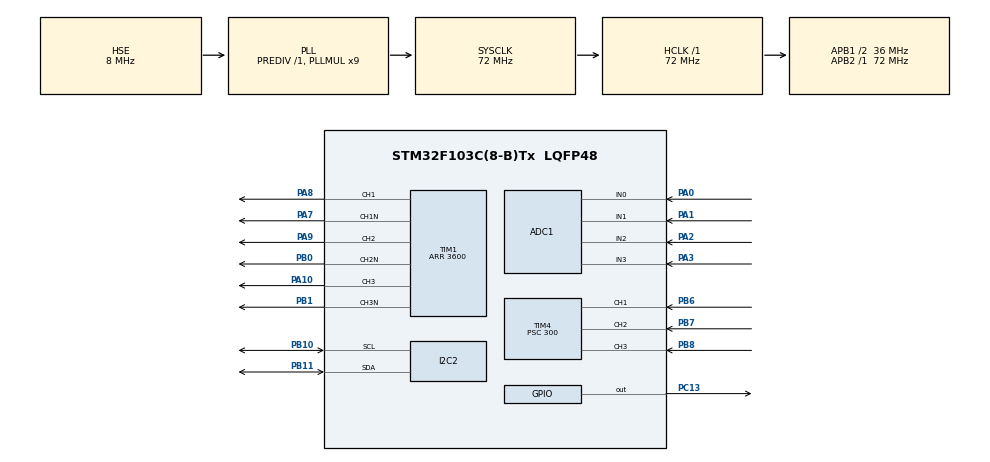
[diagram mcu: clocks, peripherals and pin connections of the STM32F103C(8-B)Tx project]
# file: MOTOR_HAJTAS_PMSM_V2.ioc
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ADC1.Channel-22\#ChannelInjectedConversion=ADC_CHANNEL_0
ADC1.Channel-24\#ChannelInjectedConversion=ADC_CHANNEL_1
ADC1.Channel-25\#ChannelInjectedConversion=ADC_CHANNEL_2
ADC1.Channel-26\#ChannelInjectedConversion=ADC_CHANNEL_3
ADC1.ContinuousConvMode=DISABLE
ADC1.DataAlign=ADC_DATAALIGN_RIGHT
ADC1.DiscontinuousConvMode=DISABLE
ADC1.EnableInjectedConversion=ENABLE
ADC1.EnableRegularConversion=DISABLE
ADC1.ExternalTrigInjecConv=ADC_EXTERNALTRIGINJECCONV_T1_TRGO
ADC1.InjNumberOfConversion=4
ADC1.InjectedConvMode=None
ADC1.InjectedOffset-22\#ChannelInjectedConversion=0
ADC1.InjectedOffset-24\#ChannelInjectedConversion=0
ADC1.InjectedOffset-25\#ChannelInjectedConversion=0
ADC1.InjectedOffset-26\#ChannelInjectedConversion=0
ADC1.Rank-22\#ChannelInjectedConversion=1
ADC1.Rank-24\#ChannelInjectedConversion=2
ADC1.Rank-25\#ChannelInjectedConversion=3
ADC1.Rank-26\#ChannelInjectedConversion=4
ADC1.SamplingTime-22\#ChannelInjectedConversion=ADC_SAMPLETIME_55CYCLES_5
ADC1.SamplingTime-24\#ChannelInjectedConversion=ADC_SAMPLETIME_55CYCLES_5
ADC1.SamplingTime-25\#ChannelInjectedConversion=ADC_SAMPLETIME_55CYCLES_5
ADC1.SamplingTime-26\#ChannelInjectedConversion=ADC_SAMPLETIME_55CYCLES_5
ADC1.master=1
Mcu.Family=STM32F1
Mcu.Name=STM32F103C(8-B)Tx
Mcu.Package=LQFP48
NVIC.ADC1_2_IRQn=true\:2\:0\:true\:false\:true\:true\:true
NVIC.PriorityGroup=NVIC_PRIORITYGROUP_4
NVIC.TIM1_UP_IRQn=true\:0\:0\:true\:false\:true\:true\:true
NVIC.TIM4_IRQn=true\:1\:0\:true\:true\:true\:1\:true\:true
PA0-WKUP.Signal=ADCx_IN0
PA1.Signal=ADCx_IN1
PA10.Signal=S_TIM1_CH3
PA13.Mode=Serial_Wire
PA13.Signal=SYS_JTMS-SWDIO
PA14.Mode=Serial_Wire
PA14.Signal=SYS_JTCK-SWCLK
PA2.Signal=ADCx_IN2
PA3.Signal=ADCx_IN3
PA7.Mode=PWM Generation1 CH1 CH1N
PA7.Signal=TIM1_CH1N
PA8.Signal=S_TIM1_CH1
PA9.Signal=S_TIM1_CH2
PB0.Mode=PWM Generation2 CH2 CH2N
PB0.Signal=TIM1_CH2N
PB1.Mode=PWM Generation3 CH3 CH3N
PB1.Signal=TIM1_CH3N
PB10.Mode=I2C
PB10.Signal=I2C2_SCL
PB11.Mode=I2C
PB11.Signal=I2C2_SDA
PB6.GPIO_PuPd=GPIO_PULLUP
PB6.Signal=S_TIM4_CH1
PB7.GPIO_PuPd=GPIO_PULLUP
PB7.Signal=S_TIM4_CH2
PB8.GPIO_PuPd=GPIO_PULLUP
PB8.Signal=S_TIM4_CH3
PC13-TAMPER-RTC.Signal=GPIO_Output
PD0-OSC_IN.Mode=HSE-External-Oscillator
PD0-OSC_IN.Signal=RCC_OSC_IN
PD1-OSC_OUT.Mode=HSE-External-Oscillator
PD1-OSC_OUT.Signal=RCC_OSC_OUT
ProjectManager.HeapSize=0x200
ProjectManager.StackSize=0x400
ProjectManager.TargetToolchain=STM32CubeIDE
RCC.ADCPresc=RCC_ADCPCLK2_DIV6
RCC.AHBFreq_Value=72000000
RCC.APB1CLKDivider=RCC_HCLK_DIV2
RCC.APB1Freq_Value=36000000
RCC.APB1TimFreq_Value=72000000
RCC.APB2Freq_Value=72000000
RCC.APB2TimFreq_Value=72000000
RCC.HCLKFreq_Value=72000000
RCC.PLLMUL=RCC_PLL_MUL9
RCC.PLLSourceVirtual=RCC_PLLSOURCE_HSE
RCC.SYSCLKFreq_VALUE=72000000
RCC.SYSCLKSource=RCC_SYSCLKSOURCE_PLLCLK
RCC.USBFreq_Value=72000000
SH.ADCx_IN0.0=ADC1_IN0,IN0
SH.ADCx_IN1.0=ADC1_IN1,IN1
SH.ADCx_IN2.0=ADC1_IN2,IN2
SH.ADCx_IN3.0=ADC1_IN3,IN3
SH.S_TIM1_CH1.0=TIM1_CH1,PWM Generation1 CH1 CH1N
SH.S_TIM1_CH2.0=TIM1_CH2,PWM Generation2 CH2 CH2N
SH.S_TIM1_CH3.0=TIM1_CH3,PWM Generation3 CH3 CH3N
SH.S_TIM4_CH1.0=TIM4_CH1,Input_Capture1_from_TI1
SH.S_TIM4_CH2.0=TIM4_CH2,Input_Capture2_from_TI2
SH.S_TIM4_CH3.0=TIM4_CH3,Input_Capture3_from_TI3
TIM1.AutoReloadPreload=TIM_AUTORELOAD_PRELOAD_ENABLE
TIM1.BreakState=TIM_BREAK_DISABLE
TIM1.Channel-PWM\ Generation1\ CH1\ CH1N=TIM_CHANNEL_1
TIM1.Channel-PWM\ Generation2\ CH2\ CH2N=TIM_CHANNEL_2
TIM1.Channel-PWM\ Generation3\ CH3\ CH3N=TIM_CHANNEL_3
TIM1.CounterMode=TIM_COUNTERMODE_CENTERALIGNED1
TIM1.DeadTime=50
TIM1.OCMode_PWM-PWM\ Generation1\ CH1\ CH1N=TIM_OCMODE_PWM2
TIM1.OCMode_PWM-PWM\ Generation2\ CH2\ CH2N=TIM_OCMODE_PWM2
TIM1.OCMode_PWM-PWM\ Generation3\ CH3\ CH3N=TIM_OCMODE_PWM2
TIM1.OffStateRunMode=TIM_OSSR_ENABLE
TIM1.Period=3600
TIM1.RepetitionCounter=1
TIM1.TIM_MasterOutputTrigger=TIM_TRGO_UPDATE
TIM1.TIM_MasterSlaveMode=TIM_MASTERSLAVEMODE_DISABLE
TIM4.Channel-Input_Capture1_from_TI1=TIM_CHANNEL_1
TIM4.Channel-Input_Capture2_from_TI2=TIM_CHANNEL_2
TIM4.Channel-Input_Capture3_from_TI3=TIM_CHANNEL_3
TIM4.ICFilter_CH1=5
TIM4.Prescaler=300
VP_TIM1_VS_ClockSourceINT.Mode=Internal
VP_TIM4_VS_ClockSourceINT.Mode=Internal
board=custom

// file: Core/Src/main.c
/* USER CODE BEGIN Header */
/**
  ******************************************************************************
  * @file           : main.c
  * @brief          : Main program body
  ******************************************************************************
  * @attention
  *
  * <h2><center>&copy; Copyright (c) 2021 STMicroelectronics.
  * All rights reserved.</center></h2>
  *
  * This software component is licensed by ST under BSD 3-Clause license,
  * the "License"; You may not use this file except in compliance with the
  * License. You may obtain a copy of the License at:
  *                        opensource.org/licenses/BSD-3-Clause
  *
  ******************************************************************************
  */
/* USER CODE END Header */
#include "main.h"

/* USER CODE BEGIN Includes */
#include "real_main.h"

/* USER CODE END Includes */

ADC_HandleTypeDef hadc1;

I2C_HandleTypeDef hi2c2;

TIM_HandleTypeDef htim1;
TIM_HandleTypeDef htim4;

void SystemClock_Config(void);
static void MX_GPIO_Init(void);
static void MX_TIM1_Init(void);
static void MX_I2C2_Init(void);
static void MX_ADC1_Init(void);
static void MX_TIM4_Init(void);
static void MX_NVIC_Init(void);

int main(void)
{

  /* MCU Configuration--------------------------------------------------------*/

  /* Reset of all peripherals, Initializes the Flash interface and the Systick. */
  HAL_Init();

  /* Configure the system clock */
  SystemClock_Config();

  /* Initialize all configured peripherals */
  MX_GPIO_Init();
  MX_TIM1_Init();
  MX_I2C2_Init();
  MX_ADC1_Init();
  MX_TIM4_Init();

  /* Initialize interrupts */
  MX_NVIC_Init();
  /* USER CODE BEGIN 2 */

  init_peripheral();

  /* USER CODE END 2 */

  /* Infinite loop */
  /* USER CODE BEGIN WHILE */
  while (1)
  {

	  main_loop();

    /* USER CODE END WHILE */

  }
}

void SystemClock_Config(void)
{
  RCC_OscInitTypeDef RCC_OscInitStruct = {0};
  RCC_ClkInitTypeDef RCC_ClkInitStruct = {0};
  RCC_PeriphCLKInitTypeDef PeriphClkInit = {0};

  /** Initializes the RCC Oscillators according to the specified parameters
  * in the RCC_OscInitTypeDef structure.
  */
  RCC_OscInitStruct.OscillatorType = RCC_OSCILLATORTYPE_HSE;
  RCC_OscInitStruct.HSEState = RCC_HSE_ON;
  RCC_OscInitStruct.HSEPredivValue = RCC_HSE_PREDIV_DIV1;
  RCC_OscInitStruct.HSIState = RCC_HSI_ON;
  RCC_OscInitStruct.PLL.PLLState = RCC_PLL_ON;
  RCC_OscInitStruct.PLL.PLLSource = RCC_PLLSOURCE_HSE;
  RCC_OscInitStruct.PLL.PLLMUL = RCC_PLL_MUL9;
  if (HAL_RCC_OscConfig(&RCC_OscInitStruct) != HAL_OK)
  {
    Error_Handler();
  }
  /** Initializes the CPU, AHB and APB buses clocks
  */
  RCC_ClkInitStruct.ClockType = RCC_CLOCKTYPE_HCLK|RCC_CLOCKTYPE_SYSCLK
                              |RCC_CLOCKTYPE_PCLK1|RCC_CLOCKTYPE_PCLK2;
  RCC_ClkInitStruct.SYSCLKSource = RCC_SYSCLKSOURCE_PLLCLK;
  RCC_ClkInitStruct.AHBCLKDivider = RCC_SYSCLK_DIV1;
  RCC_ClkInitStruct.APB1CLKDivider = RCC_HCLK_DIV2;
  RCC_ClkInitStruct.APB2CLKDivider = RCC_HCLK_DIV1;

  if (HAL_RCC_ClockConfig(&RCC_ClkInitStruct, FLASH_LATENCY_2) != HAL_OK)
  {
    Error_Handler();
  }
  PeriphClkInit.PeriphClockSelection = RCC_PERIPHCLK_ADC;
  PeriphClkInit.AdcClockSelection = RCC_ADCPCLK2_DIV6;
  if (HAL_RCCEx_PeriphCLKConfig(&PeriphClkInit) != HAL_OK)
  {
    Error_Handler();
  }
}

/**
  * @brief NVIC Configuration.
  * @retval None
  */
static void MX_NVIC_Init(void)
{
  /* TIM4_IRQn interrupt configuration */
  HAL_NVIC_SetPriority(TIM4_IRQn, 1, 0);
  HAL_NVIC_EnableIRQ(TIM4_IRQn);
}

static void MX_ADC1_Init(void)
{

  ADC_InjectionConfTypeDef sConfigInjected = {0};

  /** Common config
  */
  hadc1.Instance = ADC1;
  hadc1.Init.ScanConvMode = ADC_SCAN_ENABLE;
  hadc1.Init.ContinuousConvMode = DISABLE;
  hadc1.Init.DiscontinuousConvMode = DISABLE;
  hadc1.Init.ExternalTrigConv = ADC_SOFTWARE_START;
  hadc1.Init.DataAlign = ADC_DATAALIGN_RIGHT;
  hadc1.Init.NbrOfConversion = 1;
  if (HAL_ADC_Init(&hadc1) != HAL_OK)
  {
    Error_Handler();
  }
  /** Configure Injected Channel
  */
  sConfigInjected.InjectedChannel = ADC_CHANNEL_0;
  sConfigInjected.InjectedRank = ADC_INJECTED_RANK_1;
  sConfigInjected.InjectedNbrOfConversion = 4;
  sConfigInjected.InjectedSamplingTime = ADC_SAMPLETIME_55CYCLES_5;
  sConfigInjected.ExternalTrigInjecConv = ADC_EXTERNALTRIGINJECCONV_T1_TRGO;
  sConfigInjected.AutoInjectedConv = DISABLE;
  sConfigInjected.InjectedDiscontinuousConvMode = DISABLE;
  sConfigInjected.InjectedOffset = 0;
  if (HAL_ADCEx_InjectedConfigChannel(&hadc1, &sConfigInjected) != HAL_OK)
  {
    Error_Handler();
  }
  /** Configure Injected Channel
  */
  sConfigInjected.InjectedChannel = ADC_CHANNEL_1;
  sConfigInjected.InjectedRank = ADC_INJECTED_RANK_2;
  if (HAL_ADCEx_InjectedConfigChannel(&hadc1, &sConfigInjected) != HAL_OK)
  {
    Error_Handler();
  }
  /** Configure Injected Channel
  */
  sConfigInjected.InjectedChannel = ADC_CHANNEL_2;
  sConfigInjected.InjectedRank = ADC_INJECTED_RANK_3;
  if (HAL_ADCEx_InjectedConfigChannel(&hadc1, &sConfigInjected) != HAL_OK)
  {
    Error_Handler();
  }
  /** Configure Injected Channel
  */
  sConfigInjected.InjectedChannel = ADC_CHANNEL_3;
  sConfigInjected.InjectedRank = ADC_INJECTED_RANK_4;
  if (HAL_ADCEx_InjectedConfigChannel(&hadc1, &sConfigInjected) != HAL_OK)
  {
    Error_Handler();
  }

}

static void MX_I2C2_Init(void)
{

  hi2c2.Instance = I2C2;
  hi2c2.Init.ClockSpeed = 100000;
  hi2c2.Init.DutyCycle = I2C_DUTYCYCLE_2;
  hi2c2.Init.OwnAddress1 = 0;
  hi2c2.Init.AddressingMode = I2C_ADDRESSINGMODE_7BIT;
  hi2c2.Init.DualAddressMode = I2C_DUALADDRESS_DISABLE;
  hi2c2.Init.OwnAddress2 = 0;
  hi2c2.Init.GeneralCallMode = I2C_GENERALCALL_DISABLE;
  hi2c2.Init.NoStretchMode = I2C_NOSTRETCH_DISABLE;
  if (HAL_I2C_Init(&hi2c2) != HAL_OK)
  {
    Error_Handler();
  }

}

static void MX_TIM1_Init(void)
{

  TIM_ClockConfigTypeDef sClockSourceConfig = {0};
  TIM_MasterConfigTypeDef sMasterConfig = {0};
  TIM_OC_InitTypeDef sConfigOC = {0};
  TIM_BreakDeadTimeConfigTypeDef sBreakDeadTimeConfig = {0};

  htim1.Instance = TIM1;
  htim1.Init.Prescaler = 0;
  htim1.Init.CounterMode = TIM_COUNTERMODE_CENTERALIGNED1;
  htim1.Init.Period = 3600;
  htim1.Init.ClockDivision = TIM_CLOCKDIVISION_DIV1;
  htim1.Init.RepetitionCounter = 1;
  htim1.Init.AutoReloadPreload = TIM_AUTORELOAD_PRELOAD_ENABLE;
  if (HAL_TIM_Base_Init(&htim1) != HAL_OK)
  {
    Error_Handler();
  }
  sClockSourceConfig.ClockSource = TIM_CLOCKSOURCE_INTERNAL;
  if (HAL_TIM_ConfigClockSource(&htim1, &sClockSourceConfig) != HAL_OK)
  {
    Error_Handler();
  }
  if (HAL_TIM_PWM_Init(&htim1) != HAL_OK)
  {
    Error_Handler();
  }
  sMasterConfig.MasterOutputTrigger = TIM_TRGO_UPDATE;
  sMasterConfig.MasterSlaveMode = TIM_MASTERSLAVEMODE_DISABLE;
  if (HAL_TIMEx_MasterConfigSynchronization(&htim1, &sMasterConfig) != HAL_OK)
  {
    Error_Handler();
  }
  sConfigOC.OCMode = TIM_OCMODE_PWM2;
  sConfigOC.Pulse = 0;
  sConfigOC.OCPolarity = TIM_OCPOLARITY_HIGH;
  sConfigOC.OCNPolarity = TIM_OCNPOLARITY_HIGH;
  sConfigOC.OCFastMode = TIM_OCFAST_DISABLE;
  sConfigOC.OCIdleState = TIM_OCIDLESTATE_RESET;
  sConfigOC.OCNIdleState = TIM_OCNIDLESTATE_RESET;
  if (HAL_TIM_PWM_ConfigChannel(&htim1, &sConfigOC, TIM_CHANNEL_1) != HAL_OK)
  {
    Error_Handler();
  }
  if (HAL_TIM_PWM_ConfigChannel(&htim1, &sConfigOC, TIM_CHANNEL_2) != HAL_OK)
  {
    Error_Handler();
  }
  if (HAL_TIM_PWM_ConfigChannel(&htim1, &sConfigOC, TIM_CHANNEL_3) != HAL_OK)
  {
    Error_Handler();
  }
  sBreakDeadTimeConfig.OffStateRunMode = TIM_OSSR_ENABLE;
  sBreakDeadTimeConfig.OffStateIDLEMode = TIM_OSSI_DISABLE;
  sBreakDeadTimeConfig.LockLevel = TIM_LOCKLEVEL_OFF;
  sBreakDeadTimeConfig.DeadTime = 50;
  sBreakDeadTimeConfig.BreakState = TIM_BREAK_DISABLE;
  sBreakDeadTimeConfig.BreakPolarity = TIM_BREAKPOLARITY_HIGH;
  sBreakDeadTimeConfig.AutomaticOutput = TIM_AUTOMATICOUTPUT_DISABLE;
  if (HAL_TIMEx_ConfigBreakDeadTime(&htim1, &sBreakDeadTimeConfig) != HAL_OK)
  {
    Error_Handler();
  }
  HAL_TIM_MspPostInit(&htim1);

}

static void MX_TIM4_Init(void)
{

  TIM_ClockConfigTypeDef sClockSourceConfig = {0};
  TIM_MasterConfigTypeDef sMasterConfig = {0};
  TIM_IC_InitTypeDef sConfigIC = {0};

  htim4.Instance = TIM4;
  htim4.Init.Prescaler = 300;
  htim4.Init.CounterMode = TIM_COUNTERMODE_UP;
  htim4.Init.Period = 65535;
  htim4.Init.ClockDivision = TIM_CLOCKDIVISION_DIV1;
  htim4.Init.AutoReloadPreload = TIM_AUTORELOAD_PRELOAD_DISABLE;
  if (HAL_TIM_Base_Init(&htim4) != HAL_OK)
  {
    Error_Handler();
  }
  sClockSourceConfig.ClockSource = TIM_CLOCKSOURCE_INTERNAL;
  if (HAL_TIM_ConfigClockSource(&htim4, &sClockSourceConfig) != HAL_OK)
  {
    Error_Handler();
  }
  if (HAL_TIM_IC_Init(&htim4) != HAL_OK)
  {
    Error_Handler();
  }
  sMasterConfig.MasterOutputTrigger = TIM_TRGO_RESET;
  sMasterConfig.MasterSlaveMode = TIM_MASTERSLAVEMODE_DISABLE;
  if (HAL_TIMEx_MasterConfigSynchronization(&htim4, &sMasterConfig) != HAL_OK)
  {
    Error_Handler();
  }
  sConfigIC.ICPolarity = TIM_INPUTCHANNELPOLARITY_RISING;
  sConfigIC.ICSelection = TIM_ICSELECTION_DIRECTTI;
  sConfigIC.ICPrescaler = TIM_ICPSC_DIV1;
  sConfigIC.ICFilter = 5;
  if (HAL_TIM_IC_ConfigChannel(&htim4, &sConfigIC, TIM_CHANNEL_1) != HAL_OK)
  {
    Error_Handler();
  }
  sConfigIC.ICFilter = 0;
  if (HAL_TIM_IC_ConfigChannel(&htim4, &sConfigIC, TIM_CHANNEL_2) != HAL_OK)
  {
    Error_Handler();
  }
  if (HAL_TIM_IC_ConfigChannel(&htim4, &sConfigIC, TIM_CHANNEL_3) != HAL_OK)
  {
    Error_Handler();
  }

}

static void MX_GPIO_Init(void)
{
  GPIO_InitTypeDef GPIO_InitStruct = {0};

  /* GPIO Ports Clock Enable */
  __HAL_RCC_GPIOC_CLK_ENABLE();
  __HAL_RCC_GPIOD_CLK_ENABLE();
  __HAL_RCC_GPIOA_CLK_ENABLE();
  __HAL_RCC_GPIOB_CLK_ENABLE();

  /*Configure GPIO pin Output Level */
  HAL_GPIO_WritePin(GPIOC, GPIO_PIN_13, GPIO_PIN_RESET);

  /*Configure GPIO pin : PC13 */
  GPIO_InitStruct.Pin = GPIO_PIN_13;
  GPIO_InitStruct.Mode = GPIO_MODE_OUTPUT_PP;
  GPIO_InitStruct.Pull = GPIO_NOPULL;
  GPIO_InitStruct.Speed = GPIO_SPEED_FREQ_LOW;
  HAL_GPIO_Init(GPIOC, &GPIO_InitStruct);

}

void Error_Handler(void)
{
  __disable_irq();
  while (1)
  {
  }
}

/************************ (C) COPYRIGHT STMicroelectronics *****END OF FILE****/
